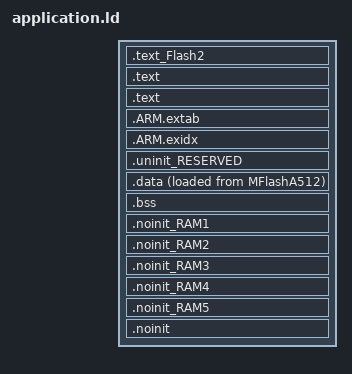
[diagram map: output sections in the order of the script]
INCLUDE "application_MEM.ld"

ENTRY(ResetISR)

SECTIONS
{
  
    .text_Flash2 : ALIGN(4)
    {
       FILL(0xff)
    	*(.text_Flash2*) /* for compatibility with previous releases */
    	*(.text_MFlashB512*) /* for compatibility with previous releases */
    	*(.text.$Flash2*)
    	*(.text.$MFlashB512*)
    	*(.rodata.$Flash2*)
    	*(.rodata.$MFlashB512*)
    } > MFlashB512

/* MAIN TEXT SECTION */
    .text : ALIGN(4)
    {
        FILL(0xff)
        __vectors_start__ = ABSOLUTE(.) ;
        KEEP(*(.isr_vector))
        /* Global Section Table */
        . = ALIGN(4) ; 
        __section_table_start = .;
        __data_section_table = .;
        LONG(LOADADDR(.data));
        LONG(    ADDR(.data));
        LONG(  SIZEOF(.data));
        __data_section_table_end = .;
        __bss_section_table = .;
        LONG(    ADDR(.bss));
        LONG(  SIZEOF(.bss));
        __bss_section_table_end = .;
        __section_table_end = . ;
	    /* End of Global Section Table */

        *(.after_vectors*)

    } >MFlashA512

    .text : ALIGN(4)    
    {
        *(.text*)
        *(.rodata .rodata.* .constdata .constdata.*)
        . = ALIGN(4);
    } > MFlashA512

    /*
     * for exception handling/unwind - some Newlib functions (in common
     * with C++ and STDC++) use this. 
     */
    .ARM.extab : ALIGN(4) 
    {
        *(.ARM.extab* .gnu.linkonce.armextab.*)
    } > MFlashA512
    __exidx_start = .;

    .ARM.exidx : ALIGN(4)
    {
        *(.ARM.exidx* .gnu.linkonce.armexidx.*)
    } > MFlashA512
    __exidx_end = .;

    _etext = .;
        
/* MAIN DATA SECTION */
    .uninit_RESERVED : ALIGN(4)
    {
        KEEP(*(.bss.$RESERVED*))
        . = ALIGN(4) ;
        _end_uninit_RESERVED = .;
    } > RamAHB16


/* MAIN DATA section (RamAHB16) */
    .data : ALIGN(4)
    {
       FILL(0xff)
       _data = . ;
       *(vtable)
       *(.ramfunc*)
       *(.data*)
       . = ALIGN(4) ;
       _edata = . ;
    } > RamAHB16 AT>MFlashA512


/* MAIN BSS SECTION (RamAHB16) */
    .bss : ALIGN(4)
    {
        _bss = .;
        *(.bss*)
        *(COMMON)
        . = ALIGN(4) ;
        _ebss = .;
        PROVIDE(end = .);
    } > RamAHB16


/* NOINIT section for RamLoc40 */
    .noinit_RAM1 (NOLOAD) : ALIGN(4)
    {
       *(.noinit.$RAM1*)
       *(.noinit.$RamLoc40*)
       . = ALIGN(4) ;
    } > RamLoc40 


/* NOINIT section for RamAHB32 */
    .noinit_RAM2 (NOLOAD) : ALIGN(4)
    {
       *(.noinit.$RAM2*)
       *(.noinit.$RamAHB32*)
       . = ALIGN(4) ;
    } > RamAHB32 


/* NOINIT section for RamAHB16 */
    .noinit_RAM3 (NOLOAD) : ALIGN(4)
    {
       *(.noinit.$RAM3*)
       *(.noinit.$RamAHB16*)
       . = ALIGN(4) ;
    } > RamAHB16 


/* NOINIT section for RamLoc32 */
    .noinit_RAM4 (NOLOAD) : ALIGN(4)
    {
       *(.noinit.$RAM4*)
       *(.noinit.$RamLoc32*)
       . = ALIGN(4) ;
    } > RamLoc32 


/* NOINIT section for RamAHB_ETB16 */
    .noinit_RAM5 (NOLOAD) : ALIGN(4)
    {
       *(.noinit.$RAM5*)
       *(.noinit.$RamAHB_ETB16*)
       . = ALIGN(4) ;
    } > RamAHB_ETB16 


/* DEFAULT NOINIT SECTION */
    .noinit (NOLOAD): ALIGN(4)
    {
        _noinit = .;
        *(.noinit*) 
         . = ALIGN(4) ;
        _end_noinit = .;
    } > RamAHB16

    PROVIDE(_vStackTop = __top_RamAHB16);

    /* ## Create checksum value (used in startup) ## */
    PROVIDE(__valid_user_code_checksum = 0 - 
                                         (_vStackTop 
                                         + (ResetISR + 1) 
                                         + (NMI_Handler + 1) 
                                         + (HardFault_Handler + 1) 
                                         + (( DEFINED(MemManage_Handler) ? MemManage_Handler : 0 ) + 1)   /* MemManage_Handler may not be defined */
                                         + (( DEFINED(BusFault_Handler) ? BusFault_Handler : 0 ) + 1)     /* BusFault_Handler may not be defined */
                                         + (( DEFINED(UsageFault_Handler) ? UsageFault_Handler : 0 ) + 1) /* UsageFault_Handler may not be defined */
                                         ) );
}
